# NUC2201AE_v1 register map
File version: 1.0
Registers are 32-bit, read-write, reset 0x0 unless marked. A register's access mark holds for its fields unless they carry their own. Offsets are from the block's base; [hi:lo] are bit positions; {n}, {i} and the like mark numbered series; 'fields as' and 'values as' point back to an identical list.

## ADC — ADC Register Map
Base 0x400E0000
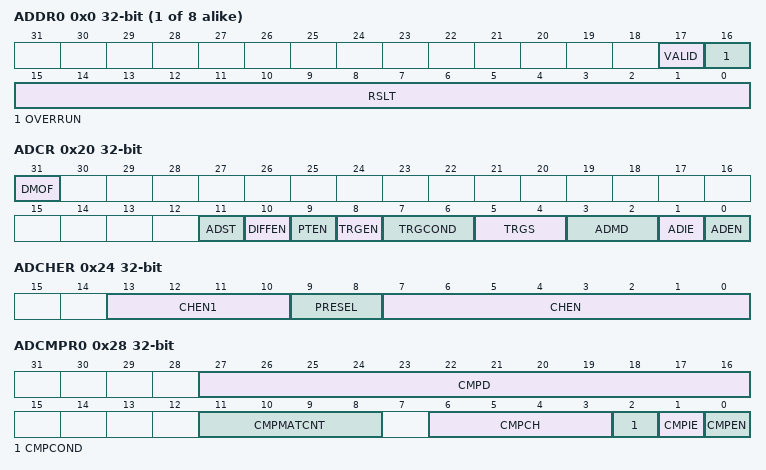
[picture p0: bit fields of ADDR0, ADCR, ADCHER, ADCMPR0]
{0x0+4i} ADDR{i} ro (i=0..7) — ADC Data Register {i}
  [17] VALID — Valid Flag. This bit is set to 1 when corresponding channel analog input conversion is completed and cleared by hardware after ADDR register is read. This is a read only bit
    0=Data in RSLT bits (ADDRx[15:0], x=0~7) is not valid; 1=Data in RSLT bits (ADDRx[15:0], x=0~7) is valid
  [16] OVERRUN — Overrun Flag. If converted data in RSLT has not been read before new conversion result is loaded to this register, OVERRUN is set to 1 and previous conversion result is gone. It is cleared by hardware after ADDR register is read. This is a read only bit.
    0=Data in RSLT (ADDRx[15:0], x=0~11) is recent conversion result; 1=Data in RSLT (ADDRx[15:0], x=0~11) is overwritten
  [15:0] RSLT — A/D Conversion Result. This field contains conversion result of ADC.
0x20 ADCR — ADC Control Register
  [31] DMOF — A/D Differential Input Mode Output Format
    0=A/D Conversion result will be filled in RSLT at ADDRx registers with unsigned format; 1=A/D Conversion result will be filled in RSLT at ADDRx registers with 2'complement format
  [11] ADST — A/D Conversion Start. ADST bit can be set to 1 from three sources: software, PWM Center-aligned trigger and external pin STADC. ADST will be cleared to 0 by hardware automatically at the ends of single mode and single-cycle scan mode. In continuous scan mode, A/D conversion is continuously performed until software writes 0 to this bit or chip reset.
    0=Conversion stops and A/D converter enter idle state; 1=Conversion starts
  [10] DIFFEN — Differential Input Mode Control
    0=Single-end analog input mode; 1=Differential analog input mode
  [9] PTEN — PDMA Transfer Enable Bit
    0=PDMA data transfer Disabled; 1=PDMA data transfer in ADDR 0~11 Enabled
  [8] TRGEN — Hardware Trigger Enable Bit. Enable or disable triggering of A/D conversion by hardware (external STADC pin or PWM Center-aligned trigger). ADC hardware trigger function is only supported in single-cycle scan mode. If hardware trigger mode, the ADST bit (ADCR[11]) can be set to 1 by the selected hardware trigger source.
    0=Disabled; 1=Enabled
  [7:6] TRGCOND — External Trigger Condition. These two bits decide external pin STADC trigger event is level or edge. The signal must be kept at stable state at least 8 PCLKs for level trigger and 4 PCLKs at high and low state for edge trigger.
    0=Low level; 1=High level; 2=Falling edge; 3=Rising edge
  [5:4] TRGS — Hardware Trigger Source. Software should disable TRGEN (ADCR[8]) and ADST (ADCR[11]) before change TRGS.
    0=A/D conversion is started by external STADC pin; 3=A/D conversion is started by PWM Center-aligned trigger
  [3:2] ADMD — A/D Converter Operation Mode. When changing the operation mode, software should disable ADST bit (ADCR[11]) firstly.
    0=Single conversion; 2=Single-cycle scan; 3=Continuous scan
  [1] ADIE — A/D Interrupt Enable Bit. A/D conversion end interrupt request is generated if ADIE bit (ADCR[1]) is set to 1.
    0=A/D interrupt function Disabled; 1=A/D interrupt function Enabled
  [0] ADEN — A/D Converter Enable Bit. Before starting A/D conversion function, this bit should be set to 1. Clear it to 0 to disable A/D converter analog circuit for saving power consumption.
    0=Disabled; 1=Enabled
0x24 ADCHER — ADC Channel Enable Register
  [13:10] CHEN1 — Analog Input Channel Enable Bit 1. Set CHEN[14:10] to enable the corresponding analog input channel 11 ~ 8. If DIFFEN bit (ADCR[10]) is set to 1, only the even number channels need to be enabled.
    0=ADC input channel Disabled; 1=ADC input channel Enabled
  [9:8] PRESEL — Analog Input Channel 7 Selection
    0=External analog input; 1=Internal band-gap voltage; 2=Internal temperature sensor
  [7:0] CHEN — Analog Input Channel Enable Bit. Set CHEN[7:0] to enable the corresponding analog input channel 7 ~ 0. If DIFFEN bit (ADCR[10]) is set to 1, only the even number channels need to be enabled.
    0=ADC input channel Disabled; 1=ADC input channel Enabled
0x28 ADCMPR0 — ADC Compare Register 0
  [27:16] CMPD — Comparison Data. The 12-bit data is used to compare with conversion result of specified channel. When DMOF bit (ADCR[31]) is set to 0, ADC comparator compares CMPD with conversion result with unsigned format. CMPD should be filled in unsigned format. When DMOF bit (ADCR[31]) is set to 1, ADC comparator compares CMPD with conversion result with 2'complement format. CMPD should be filled in 2'complement format.
  [11:8] CMPMATCNT — Compare Match Count. When the specified A/D channel analog conversion result matches the compare condition defined by CMPCOND (ADCMPR0/1[2]), the internal match counter will increase 1, The comparing data must successively matched with the compare condition. Once any comparing data does not match during the comparing, the internal counter will clear to 0. When the internal counter reaches the value to (CMPMATCNT (ADCMPR0/1[11:8]) +1), the CMPF0/1 bit (ADSR[1]/[2]) will be set.
  [6:3] CMPCH — Compare Channel Selection
    {v}=Channel {v} conversion result is selected to be compared (v=0..11)
  [2] CMPCOND — Compare Condition. Note: When the internal counter reaches the value to (CMPMATCNT (ADCMPR0/1[11:8])+1), the CMPF0/1 bit (ADSR[1]/[2]) will be set.
    0=Set the compare condition as that when a 12-bit A/D conversion result is less than the 12-bit CMPD (ADCMPR0/1[27:16]), the internal match counter will increase one; 1=Set the compare condition as that when a 12-bit A/D conversion result is greater or equal to the 12-bit CMPD (ADCMPR0/1[27:16]), the internal match counter will increase one
  [1] CMPIE — Compare Interrupt Enable Bit. If the compare function is enabled and the compare condition matches the setting of CMPCOND (ADCMPR0/1[2]) and CMPMATCNT (ADCMPR0/1[11:8]), CMPF0/1 bit (ADSR[1]/[2]) will be asserted, in the meanwhile, if CMPIE (ADCMPR0/1[1]) is set to 1, a compare interrupt request is generated.
    0=Compare function interrupt Disabled; 1=Compare function interrupt Enabled
  [0] CMPEN — Compare Enable Bit. Set this bit to 1 to enable ADC controller to compare CMPD (ADCMPR0/1[27:16]) with specified channel conversion result when converted data is loaded into ADDR register.
    0=Compare function Disabled; 1=Compare function Enabled
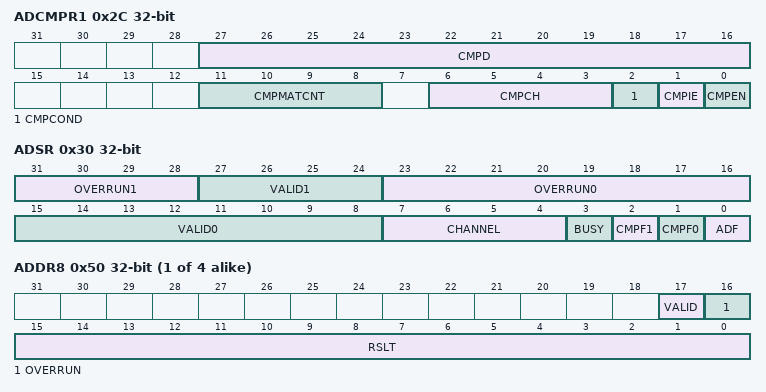
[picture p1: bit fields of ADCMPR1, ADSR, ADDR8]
0x2C ADCMPR1 — ADC Compare Register 1
  fields as ADCMPR0
0x30 ADSR — ADC Status Register
  [31:28] OVERRUN1 — Overrun Flag. It is a mirror to OVERRUN bit (ADDR8~11[16]). It is read only.
  [27:24] VALID1 — Data Valid Flag. It is a mirror of VALID bit (ADDR8~11[17]). It is read only.
  [23:16] OVERRUN0 — Overrun Flag. It is a mirror to OVERRUN bit (ADDR0~7[16]). It is read only.
  [15:8] VALID0 — Data Valid Flag. It is a mirror of VALID bit (ADDR0~7[17]). It is read only.
  [7:4] CHANNEL — Current Conversion Channel. It is read only.
  [3] BUSY — BUSY/IDLE. This bit is mirror of as ADST bit (ADCR[11]). It is read only.
    0=A/D converter is in idle state; 1=A/D converter is busy at conversion
  [2] CMPF1 — Compare Flag. When the selected channel A/D conversion result meets setting condition in ADCMPR1 then this bit is set to 1. And it is cleared by writing 1 to self.
    0=Conversion result in ADDR does not meet ADCMPR1 setting; 1=Conversion result in ADDR meets ADCMPR1 setting
  [1] CMPF0 — Compare Flag. When the selected channel A/D conversion result meets setting condition in ADCMPR0 then this bit is set to 1. And it is cleared by writing 1 to self.
    0=Conversion result in ADDR does not meet ADCMPR0 setting; 1=Conversion result in ADDR meets ADCMPR0 setting
  [0] ADF — A/D Conversion End Flag. A status flag that indicates the end of A/D conversion. ADF is set to 1 at these two conditions: 1. When A/D conversion ends in Single mode. 2. When A/D conversion ends on all specified channels in Scan mode. This flag can be cleared by writing 1 to itself.
0x40 ADPDMA ro — ADC PDMA Current Transfer Data Register
  [17:0] AD_PDMA — ADC PDMA Current Transfer Data Register. When PDMA transferring, read this register can monitor current PDMA transfer data. Current PDMA transfer data is the content of ADDR0 ~ ADDR11. This is a read only register.
{0x30+4i} ADDR{i} ro (i=8..11) — ADC Data Register {i}
  fields as ADDR0
